# IWRL6432 register map
File version: 1.0
CPU: CM4 1.0, other endian, MPU, FPU, 3 interrupt priority bits
Registers are 32-bit, read-write, reset 0x0 unless marked. A register's access mark holds for its fields unless they carry their own. Offsets are from the block's base; [hi:lo] are bit positions; {n}, {i} and the like mark numbered series.

## APP_CRC
Base 0x54020000
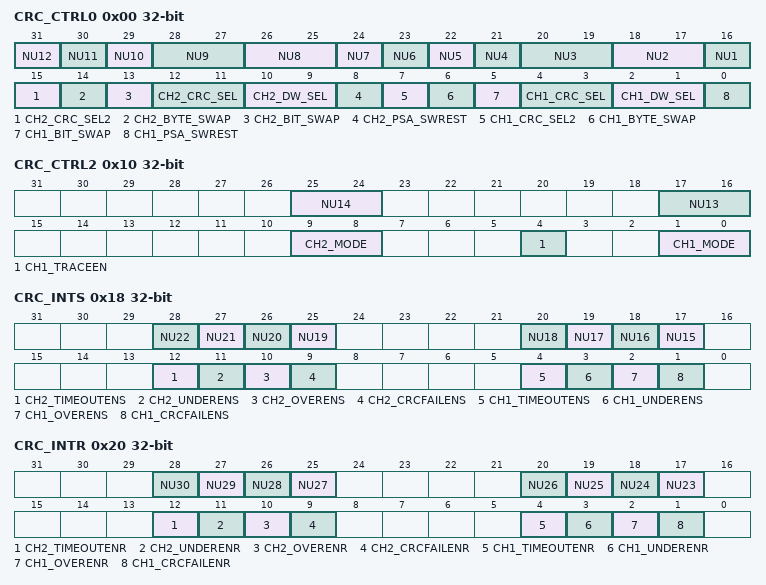
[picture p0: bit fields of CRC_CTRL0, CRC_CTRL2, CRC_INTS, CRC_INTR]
0x00 CRC_CTRL0 — Contains sw reset control bit to reset PSA
  [31] NU12 — [31:31] Reserved
  [30] NU11 — [30:30] Reserved
  [29] NU10 — [29:29] Reserved
  [28:27] NU9 — [28:27] Reserved
  [26:25] NU8 — [26:25] Reserved
  [n+17] NU{n} (n=4..7) — [{n+17}:{n+17}] Reserved
  [20:19] NU3 — [20:19] Reserved
  [18:17] NU2 — [18:17] Reserved
  [16] NU1 — [16:16] Reserved
  [15] CH2_CRC_SEL2 — [15:15] Refer "CH2_DW_SEL" field description
  [14] CH2_BYTE_SWAP — [14:14] BYTE SWAP Enable across Data Size 0 ΓÇô Byte Swap Disabled 1 ΓÇô Byte Swap enabled.
  [13] CH2_BIT_SWAP — [13:13] msb/lsb SWAPPING 0 ΓÇô msb (most significant bit First) 1 ΓÇô lsb (least significant bit First)
  [12:11] CH2_CRC_SEL — [12:11] CRC type select. {CH1_CRC_SEL2,CH1_CRC_SEL[1:0]} 000 ΓÇô CRC-64 001 - CRC-16 010 ΓÇô CRC-32 100 - VDA CAN, SAE-J1850 CRC-8 101 - H2F, Autosar 4.0 110 - CASTAGNOLI, iSCSI 111 / 011 - E2E Profile 4
  [10:9] CH2_DW_SEL — [10:9] CRC Data Size select. 000 ΓÇô Not Supported 001 - 16 bit Data Size 010 ΓÇô 32 Bit Data Size
  [8] CH2_PSA_SWREST — [8:8] Channel 2 PSA Software Reset. When set, the PSA Signature Register is reset to all zero. Software reset does not reset software reset bit itself. Therefore, CPU is required to clear this bit by writing a ΓÇÿ0ΓÇÖ. 0 = PSA Signature Register not reset 1 = PSA Signature Register reset
  [7] CH1_CRC_SEL2 — [7:7] Refer "CH1_DW_SEL" field description
  [6] CH1_BYTE_SWAP — [6:6] BYTE SWAP Enable across Data Size 0 ΓÇô Byte Swap Disabled 1 ΓÇô Byte Swap enabled.
  [5] CH1_BIT_SWAP — [5:5] msb/lsb SWAPPING 0 ΓÇô msb (most significant bit First) 1 ΓÇô lsb (least significant bit First)
  [4:3] CH1_CRC_SEL — [4:3] CRC type select. {CH1_CRC_SEL2,CH1_CRC_SEL[1:0]} 000 ΓÇô CRC-64 001 - CRC-16 010 ΓÇô CRC-32 100 - VDA CAN, SAE-J1850 CRC-8 101 - H2F, Autosar 4.0 110 - CASTAGNOLI, iSCSI 111 / 011 - E2E Profile 4
  [2:1] CH1_DW_SEL — [2:1] CRC Data Size select. 000 ΓÇô Not Supported 001 - 16 bit Data Size 010 ΓÇô 32 Bit Data Size
  [0] CH1_PSA_SWREST — [0:0] Channel 1 PSA Software Reset. When set, the PSA Signature Register is reset to all zero. Software reset does not reset software reset bit itself. Therefore, CPU is required to clear this bit by writing a ΓÇÿ0ΓÇÖ. 0 = PSA Signature Register not reset 1 = PSA Signature Register reset
0x08 CRC_CTRL1 — Contains power down control bit
  [0] PWDN — [0:0] Power Down. When set, MCRC moduleMCRC Module is put in power down mode. 0 = MCRC is not in power down mode 1 = MCRC is in power down mode
0x10 CRC_CTRL2 — Contains channel mode, data trace enable control bits
  [25:24] NU14 — [25:24] Reserved
  [17:16] NU13 — [17:16] Reserved
  [9:8] CH2_MODE — [9:8] Channel 2 Mode: 0 0 = Data Capture mode. In this mode, the PSA Signature Register does not compress data when it is written. Any data written to PSA Signature Register is simply captured by PSA Signature Register without any compression. This mode can be used to plant seed value into the PSA register 0 1 = AUTO mode 1 0 = reserved 1 1 = Full-CPU mode
  [4] CH1_TRACEEN — [4:4] Channel 1 Data Trace Enable. When set, the channel is put into data trace mode. The channel snoops on the CPU VBUSM, ITCM, DTCM buses for any read transaction. Any read data on these buses is compressed by the PSA Signature Register. When suspend is on, the PSA Signature Register does not compress any read data on these buses. 0 = Data Trace disable 1 = Data Trace enable
  [1:0] CH1_MODE — [1:0] Channel 1 Mode: 0 0 = Data Capture mode. In this mode, the PSA Signature Register does not compress data when it is written. Any data written to PSA Signature Register is simply captured by PSA Signature Register without any compression. This mode can be used to plant seed value into the PSA register 0 1 = AUTO mode 1 0 = reserved 1 1 = Full-CPU mode
0x18 CRC_INTS — Write one to a bit to enable a interrupt
  [n+6] NU{n} (n=19..22) — [{n+6}:{n+6}] Reserved
  [n+2] NU{n} (n=15..18) — [{n+2}:{n+2}] Reserved
  [12] CH2_TIMEOUTENS — [12:12] Channel 2 Timeout Interrupt Enable Bit. Writing a one to this bit enable the timeout interrupt. Writing a zero has no effect. Reading from this bit gives the status (interrupt enable/disable). User and privileged mode read: 0 = Timeout Interrupt disable 1 = Timeout Interrupt enable User and privileged mode write: 0 = Has no effect 1 = Timeout Interrupt enable
  [11] CH2_UNDERENS — [11:11] Channel 2 Underrun Interrupt Enable Bit. Writing a one to this bit enable the underrun interrupt. Writing a zero has no effect. Reading from this bit gives the status (interrupt enable/disable). User and privileged mode read: 0 = Underrun Interrupt disable 1 = Underrun Interrupt enable User and privileged mode write: 0 = Has no effect 1 = Underrun Interrupt enable
  [10] CH2_OVERENS — [10:10] Channel 2 Overrun Interrupt Enable Bit. Writing a one to this bit enable the overrun interrupt. Writing a zero has no effect. Reading from this bit gives the status (interrupt enable/disable). User and privileged mode read: 0 = Overrun Interrupt disable 1 = Overrun Interrupt enable User and privileged mode write: 0 = Has no effect 1 = Overrun Interrupt enable
  [9] CH2_CRCFAILENS — [9:9] Channel 2 CRC Fail Interrupt Enable Bit. Writing a one to this bit enable the CRC fail interrupt. Writing a zero has no effect. Reading from this bit gives the status (interrupt enable/disable). User and privileged mode read: 0 = CRC Fail Interrupt disable 1 = CRC Fail Interrupt enable User and privileged mode write: 0 = Has no effect 1 = CRC Fail Interrupt enable
  [4] CH1_TIMEOUTENS — [4:4] Channel 1 Timeout Interrupt Enable Bit. Writing a one to this bit enable the timeout interrupt. Writing a zero has no effect. Reading from this bit gives the status (interrupt enable/disable). User and privileged mode read: 0 = Timeout Interrupt disable 1 = Timeout Interrupt enable User and privileged mode write: 0 = Has no effect 1 = Timeout Interrupt enable
  [3] CH1_UNDERENS — [3:3] Channel 1 Underrun Interrupt Enable Bit. Writing a one to this bit enable the underrun interrupt. Writing a zero has no effect. Reading from this bit gives the status (interrupt enable/disable). User and privileged mode read: 0 = Underrun Interrupt disable 1 = Underrun Interrupt enable User and privileged mode write: 0 = Has no effect 1 = Underrun Interrupt enable
  [2] CH1_OVERENS — [2:2] Channel 1 Overrun Interrupt Enable Bit. Writing a one to this bit enable the overrun interrupt. Writing a zero has no effect. Reading from this bit gives the status (interrupt enable/disable). User and privileged mode read: 0 = Overrun Interrupt disable 1 = Overrun Interrupt enable User and privileged mode write: 0 = Has no effect 1 = Overrun Interrupt enable
  [1] CH1_CRCFAILENS — [1:1] Channel 1 CRC Fail Interrupt Enable Bit. Writing a one to this bit enable the CRC fail interrupt. Writing a zero has no effect. Reading from this bit gives the status (interrupt enable/disable). User and privileged mode read: 0 = CRC Fail Interrupt disable 1 = CRC Fail Interrupt enable User and privileged mode write: 0 = Has no effect 1 = CRC Fail Interrupt enable
0x20 CRC_INTR — Write one to a bit to disable a interrupt
  [n-2] NU{n} (n=27..30) — [{n-2}:{n-2}] Reserved
  [n-6] NU{n} (n=23..26) — [{n-6}:{n-6}] Reserved
  [12] CH2_TIMEOUTENR — [12:12] Channel 2 Timeout Interrupt Disable Bit. Writing a one to this bit disable the timeout interrupt. Writing a zero has no effect. Reading from this bit gives the status (interrupt enable/disable). User and privileged mode read: 0 = Timeout Interrupt disable 1 = Timeout Interrupt enable User and privileged mode write: 0 = Has no effect 1 = Timeout Interrupt disable
  [11] CH2_UNDERENR — [11:11] Channel 2 Underrun Interrupt Disable Bit. Writing a one to this bit disable the underrun interrupt. Writing a zero has no effect. Reading from this bit gives the status (interrupt enable/dis- able). User and privileged mode read: 0 = Underrun Interrupt disable 1 = Underrun Interrupt enable User and privileged mode write: 0 = Has no effect 1 = Underrun Interrupt disable
  [10] CH2_OVERENR — [10:10] Channel 2 Overrun Interrupt Disable Bit. Writing a one to this bit disable the overrun interrupt. Writing a zero has no effect. Reading from this bit gives the status (interrupt enable/disable). User and privileged mode read: 0 = Overrun Interrupt disable 1 = Overrun Interrupt enable User and privileged mode write: 0 = Has no effect 1 = Overrun Interrupt disable
  [9] CH2_CRCFAILENR — [9:9] Channel 2 CRC Fail Interrupt Disable Bit. Writing a one to this bit disable the CRC fail interrupt. Writing a zero has no effect. Reading from this bit gives the status (interrupt enable/disable). User and privileged mode read: 0 = CRC Fail Interrupt disable 1 = CRC Fail Interrupt enable User and privileged mode write: 0 = Has no effect 1 = CRC Fail Interrupt disable
  [4] CH1_TIMEOUTENR — [4:4] Channel 1 Timeout Interrupt Disable Bit. Writing a one to this bit disable the timeout interrupt. Writing a zero has no effect. Reading from this bit gives the status (interrupt enable/disable). User and privileged mode read: 0 = Timeout Interrupt disable 1 = Timeout Interrupt enable User and privileged mode write: 0 = Has no effect 1 = Timeout Interrupt disable
  [3] CH1_UNDERENR — [3:3] Channel 1 Underrun Interrupt Disable Bit. Writing a one to this bit disable the underrun interrupt. Writing a zero has no effect. Reading from this bit gives the status (interrupt enable/dis- able). User and privileged mode read: 0 = Underrun Interrupt disable 1 = Underrun Interrupt enable User and privileged mode write: 0 = Has no effect 1 = Underrun Interrupt disable
  [2] CH1_OVERENR — [2:2] Channel 1 Overrun Interrupt Disable Bit. Writing a one to this bit disable the overrun interrupt. Writing a zero has no effect. Reading from this bit gives the status (interrupt enable/disable). User and privileged mode read: 0 = Overrun Interrupt disable 1 = Overrun Interrupt enable User and privileged mode write: 0 = Has no effect 1 = Overrun Interrupt disable
  [1] CH1_CRCFAILENR — [1:1] Channel 1 CRC Fail Interrupt Disable Bit. Writing a one to this bit disable the CRC fail interrupt. Writing a zero has no effect. Reading from this bit gives the status (interrupt enable/disable). User and privileged mode read: 0 = CRC Fail Interrupt disable 1 = CRC Fail Interrupt enable User and privileged mode write: 0 = Has no effect 1 = CRC Fail Interrupt disable
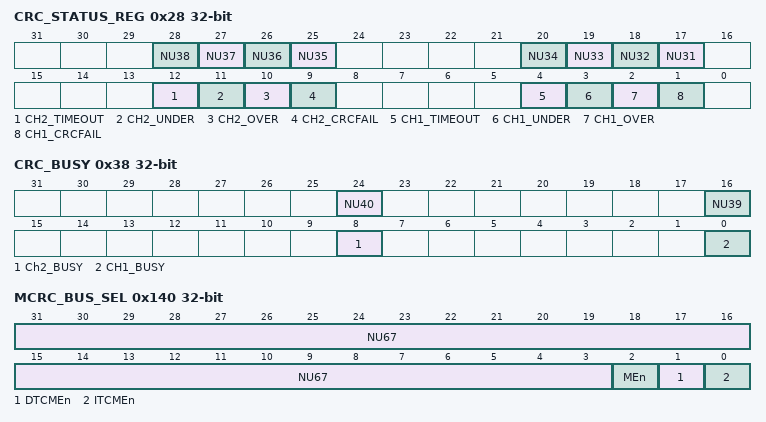
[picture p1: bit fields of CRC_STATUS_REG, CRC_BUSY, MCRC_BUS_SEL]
0x28 CRC_STATUS_REG — Contains interrupt flags for different types of interrupt
  [n-10] NU{n} (n=35..38) — [{n-10}:{n-10}] Reserved
  [n-14] NU{n} (n=31..34) — [{n-14}:{n-14}] Reserved
  [12] CH2_TIMEOUT — [12:12] Channel 2 CRC Timeout Status Flag. This bit is cleared by writing a ΓÇÖ1ΓÇÖ to it only. Writing ΓÇÖ0ΓÇÖ has no effect. This bit is set in AUTO mode. 0 = No timeout interrupt is active 1 = Timeout interrupt is active
  [11] CH2_UNDER — [11:11] Channel 2 CRC Underrun Status Flag. This bit is cleared by writing a ΓÇÖ1ΓÇÖ to it only. Writing ΓÇÖ0ΓÇÖ has no effect. This bit is set in AUTO mode only 0 = No underrun interrupt is active 1 = Underrun interrupt is active
  [10] CH2_OVER — [10:10] Channel 2 CRC Overrun Status Flag. This bit is cleared by writing a ΓÇÖ1ΓÇÖ to it only. Writing ΓÇÖ0ΓÇÖ has no effect. This bit is set in AUTO mode 0 = No overrun interrupt is active 1 = Overrun interrupt is active
  [9] CH2_CRCFAIL — [9:9] Channel 2 CRC Compare Fail Status Flag. This bit is cleared by writing a ΓÇÖ1ΓÇÖ to it only. Writing ΓÇÖ0ΓÇÖ has no effect. This bit is set in AUTO mode only. 0 = No CRC compare fail interrupt is active 1 = CRC compare fail interrupt is active
  [4] CH1_TIMEOUT — [4:4] Channel 1 CRC Timeout Status Flag. This bit is cleared by writing a ΓÇÖ1ΓÇÖ to it only. Writing ΓÇÖ0ΓÇÖ has no effect. This bit is set in AUTO mode. 0 = No timeout interrupt is active 1 = Timeout interrupt is active
  [3] CH1_UNDER — [3:3] Channel 1 CRC Underrun Status Flag. This bit is cleared by writing a ΓÇÖ1ΓÇÖ to it only. Writing ΓÇÖ0ΓÇÖ has no effect. This bit is set in AUTO mode only 0 = No underrun interrupt is active 1 = Underrun interrupt is active
  [2] CH1_OVER — [2:2] Channel 1 CRC Overrun Status Flag. This bit is cleared by writing a ΓÇÖ1ΓÇÖ to it only. Writing ΓÇÖ0ΓÇÖ has no effect. This bit is set in AUTO mode 0 = No overrun interrupt is active 1 = Overrun interrupt is active
  [1] CH1_CRCFAIL — [1:1] Channel 1 CRC Compare Fail Status Flag. This bit is cleared by writing a ΓÇÖ1ΓÇÖ to it only. Writing ΓÇÖ0ΓÇÖ has no effect. This bit is set in AUTO mode only. 0 = No CRC compare fail interrupt is active 1 = CRC compare fail interrupt is active
0x30 CRC_INT_OFFSET_REG — Contains the interrupt offset vector address
  [7:0] OFSTREG — [7:0] CRC Interrupt Offset. This register indicates the highest priority pending interrupt vector address. Reading the offset register auto- matically clear the respective interrupt flag. Please reference Table 1ΓÇô3. for details.
0x38 CRC_BUSY — Contains the busy flag for each channel
  [24] NU40 — [24:24] Reserved
  [16] NU39 — [16:16] Reserved
  [8] Ch2_BUSY — [8:8] Ch2_BUSY. During AUTO mode, the busy flag is set when the first data pattern of the block is compressed and remains set until the the last data pattern of the block is compressed. The flag is cleared when the last data pattern of the block is compressed.
  [0] CH1_BUSY — [0:0] CH1_BUSY. During AUTO mode, the busy flag is set when the first data pattern of the block is compressed and remains set until the the last data pattern of the block is compressed. The flag is cleared when the last data pattern of the block is compressed.
0x40 CRC_PCOUNT_REG1 — Channel 1 preload register for the pattern count
  [19:0] CRC_PAT_COUNT1 — [19:0] Channel 1 Pattern Counter Preload Register. This register con- tains the number of data patterns in one sector to be compressed before a CRC is performed.
0x44 CRC_SCOUNT_REG1 — Channel 1 preload register for the sector count
  [15:0] CRC_SEC_COUNT1 — [15:0] Channel 1 Sector Counter Preload Register. This register con- tains the number of sectors in one block of memory.
0x48 CRC_CURSEC_REG1 — Channel 1 current sector register contains the sector number which causes CRC failure
  [15:0] CRC_CURSEC1 — [15:0] Channel 1 Current Sector ID Register. In AUTO mode, this register contains the current sector number of which the signature verification fails. The sector counter is a free running up counter. When a sector fails, the erroneous sector number is logged into current sector ID register and the CRC fail interrupt is generated The sector ID register is frozen until it is read and the CRC fail status bit is cleared by CPU. While it is frozen, it does not capture another erroneous sector number. When this condition happens, an overrun interrupt is generated instead. Once the register is read and the CRC fail interrupt flag is cleared it can capture new erro- neous sector number.
0x4C CRC_WDTOPLD1 — Channel 1 timeout pre-load value to check if within a given time DMA initiates a block transfer
  [23:0] CRC_WDTOPLD1 — [23:0] Channel 1 Watchdog Timeout Counter Preload Register. This register contains the number of clock cycles within which the DMA must transfer the next block of data patterns.
0x50 CRC_BCTOPLD1 — Channel 1 timeout pre-load value to check if one block of patterns are compressed with a given time
  [23:0] CRC_BCTOPLD1 — [23:0] Channel 1 Block Complete Timeout Counter Preload Regis- ter. This register contains the number of clock cycles within which the CRC for an entire block needs to complete before a timeout interrupt is generated.
0x60 PSA_SIGREGL1 — Channel 1 PSA signature low register
  [31:0] PSASIG1_31_0 — [31:0] Channel 1 PSA Signature Low Register. This register contains the value stored at PSASIG1[31:0] register.
0x64 PSA_SIGREGH1 — Channel 1 PSA signature high register
  [31:0] PSA_SIG1_63_32 — [31:0] Channel 1 PSA Signature High Register. This register contains the value stored at PSASIG1[63:32] register.
0x68 CRC_REGL1 — Channel 1 CRC value low register
  [31:0] CRC1_31_0 — [31:0] Channel 1 CRC Value Low Register. This register contains the current known good signature value stored at CRC1[31:0] regis- ter.
0x6C CRC_REGH1 — Channel 1 CRC value high register
  [31:0] CRC1_63_32 — [31:0] Channel 1 CRC Value High Register. This register contains the current known good signature value stored at CRC1[63:32] regis- ter.
0x70 PSA_SECSIGREGL1 — Channel 1 PSA sector signature low regis-ter
  [31:0] PSASECSIG1_31_0 — [31:0] Channel 1 PSA Sector Signature Low Register. This register contains the value stored at PSASECSIG1[31:0] register.
0x74 PSA_SECSIGREGH1 — Channel 1 PSA sector signature high regis-ter
  [31:0] PSASECSIG1_63_32 — [31:0] Channel 1 PSA Sector Signature High Register. This register contains the value stored at PSASECSIG1[63:32] register.
0x78 RAW_DATAREGL1 — Channel 1 un-compressed raw data low register
  [31:0] RAW_DATA1_31_0 — [31:0] Channel 1 Raw Data Low Register. This register contains bit 31:0 of the un-compressed raw data.
0x7C RAW_DATAREGH1 — Channel 1 un-compressed raw data high register
  [31:0] RAW_DATA1_63_32 — [31:0] Channel 1 Raw Data High Register. This register contains bit 63:32 of the un-compressed raw data.
0x80 CRC_PCOUNT_REG2 — Channel 2 preload register for the pattern count
  [19:0] CRC_PAT_COUNT2 — [19:0] Channel 2 Pattern Counter Preload Register. This register con- tains the number of data patterns in one sector to be compressed before a CRC is performed.
0x84 CRC_SCOUNT_REG2 — Channel 2 preload register for the sector count
  [15:0] CRC_SEC_COUNT2 — [15:0] Channel 2 Sector Counter Preload Register. This register con- tains the number of sectors in one block of memory.
0x88 CRC_CURSEC_REG2 — Channel 2 current sector register contains the sector number which causes CRC fail-ure
  [15:0] CRC_CURSEC2 — [15:0] Channel 2 Current Sector ID Register. In AUTO mode, this register contains the current sector number of which the signature verification fails. The sector counter is a free running up counter. When a sector fails, the erroneous sector number is logged into current sector ID register and the CRC fail interrupt is generated The sector ID register is frozen until it is read and the CRC fail status bit is cleared by CPU. While it is frozen, it does not capture another erroneous sector number. When this condition happens, an overrun interrupt is generated instead. Once the register is read and the CRC fail interrupt flag is cleared it can capture new erro- neous sector number.
0x8C CRC_WDTOPLD2 — Channel 2 timeout pre-load value to check if within a given time DMA initiates a block transfer
  [23:0] CRC_WDTOPLD2 — [23:0] Channel 2 Watchdog Timeout Counter Preload Register. This register contains the number of clock cycles within which the DMA must transfer the next block of data patterns.
0x90 CRC_BCTOPLD2 — Channel 2 timeout pre-load value to check if one block of patterns are compressed with a given time
  [23:0] CRC_BCTOPLD2 — [23:0] Channel 2 Block Complete Timeout Counter Preload Regis- ter. This register contains the number of clock cycles within which the CRC for an entire block needs to complete before a timeout interrupt is generated.
0xA0 PSA_SIGREGL2 — Channel 2 PSA signature low register
  [31:0] PSASIG2_31_0 — [31:0] Channel 2 PSA Signature Low Register. This register contains the value stored at PSASIG2[31:0] register.
0xA4 PSA_SIGREGH2 — Channel 2 PSA signature high register
  [31:0] PSA_SIG2_63_32 — [31:0] Channel 2 PSA Signature High Register. This register contains the value stored at PSASIG2[63:32] register.
0xA8 CRC_REGL2 — Channel 2 CRC value low register
  [31:0] CRC2_31_0 — [31:0] Channel 2 CRC Value Low Register. This register contains the current known good signature value stored at CRC2[31:0] regis- ter.
0xAC CRC_REGH2 — Channel 2 CRC value high register
  [31:0] CRC2_63_32 — [31:0] Channel 2 CRC Value High Register. This register contains the current known good signature value stored at CRC2[63:32] regis- ter.
0xB0 PSA_SECSIGREGL2 — Channel 2 PSA sector signature low regis-ter
  [31:0] PSASECSIG2_31_0 — [31:0] Channel 2 PSA Sector Signature Low Register. This register contains the value stored at PSASECSIG2[31:0] register.
0xB4 PSA_SECSIGREGH2 — Channel 2 PSA sector signature high regis-ter
  [31:0] PSASECSIG2_63_32 — [31:0] Channel 2 PSA Sector Signature High Register. This register contains the value stored at PSASECSIG2[63:32] register.
0xB8 RAW_DATAREGL2 — Channel 2 un-compressed raw data low register
  [31:0] RAW_DATA2_31_0 — [31:0] Channel 2 Raw Data Low Register. This register contains bit 31:0 of the un-compressed raw data.
0xBC RAW_DATAREGH2 — Channel 2 un-compressed raw data high Register
  [31:0] RAW_DATA2_63_32 — [31:0] Channel 2 Raw Data High Register. This register contains bit 63:32 of the un-compressed raw data.
0xC0 CRC_PCOUNT_REG3 — Channel 3 preload register for the pattern count
  [19:0] NU41 — [19:0] Reserved
0xC4 CRC_SCOUNT_REG3 — Channel 3 preload register for the sector count
  [15:0] NU42 — [15:0] Reserved
0xC8 CRC_CURSEC_REG3 — Channel 3 current sector register contains the sector number which causes CRC fail-ure
  [15:0] NU43 — [15:0] Reserved
0xCC CRC_WDTOPLD3 — Channel 3 timeout pre-load value to check if within a given time DMA initiates a block transfer
  [23:0] NU44 — [23:0] Reserved
0xD0 CRC_BCTOPLD3 — Channel 3 timeout pre-load value to check if one block of patterns are compressed with a given time
  [23:0] NU45 — [23:0] Reserved
0xE0 PSA_SIGREGL3 — Channel 3 PSA signature low register
  [31:0] NU46 — [31:0] Reserved
0xE4 PSA_SIGREGH3 — Channel 3 PSA signature high register
  [31:0] NU47 — [31:0] Reserved
0xE8 CRC_REGL3 — Channel 3 CRC value low register
  [31:0] NU48 — [31:0] Reserved
0xEC CRC_REGH3 — Channel 3 CRC value high register
  [31:0] NU49 — [31:0] Reserved
0xF0 PSA_SECSIGREGL3 — Channel 3 PSA sector signature low regis-ter
  [31:0] NU50 — [31:0] Reserved
0xF4 PSA_SECSIGREGH3 — Channel 3 PSA sector signature high regis-ter
  [31:0] NU51 — [31:0] Reserved
0xF8 RAW_DATAREGL3 — Channel 3 un-compressed raw data low register
  [31:0] NU52 — [31:0] Reserved
0xFC RAW_DATAREGH3 — Channel 3 un-compressed raw data high Register
  [31:0] NU53 — [31:0] Reserved
0x100 CRC_PCOUNT_REG4 — Channel 4 preload register for the pattern count
  [19:0] NU54 — [19:0] Reserved
0x104 CRC_SCOUNT_REG4 — Channel 4 preload register for the sector count
  [15:0] NU55 — [15:0] Reserved
0x108 CRC_CURSEC_REG4 — Channel 4 current sector register contains the sector number which causes CRC fail-ure
  [15:0] NU56 — [15:0] Reserved
0x10C CRC_WDTOPLD4 — Channel 4 timeout pre-load value to check if within a given time DMA initiates a block transfer
  [23:0] NU57 — [23:0] Reserved
0x110 CRC_BCTOPLD4 — Channel 4 timeout pre-load value to check if one block of patterns are compressed with a given time
  [23:0] NU58 — [23:0] Reserved
0x120 PSA_SIGREGL4 — Channel 4 PSA signature low register
  [31:0] NU59 — [31:0] Reserved
0x124 PSA_SIGREGH4 — Channel 4 PSA signature high register
  [31:0] NU60 — [31:0] Reserved
0x128 CRC_REGL4 — Channel 4 CRC value low register
  [31:0] NU61 — [31:0] Reserved
0x12C CRC_REGH4 — Channel 4 CRC value high register
  [31:0] NU62 — [31:0] Reserved
0x130 PSA_SECSIGREGL4 — Channel 4 PSA sector signature low regis-ter
  [31:0] NU63 — [31:0] Reserved
0x134 PSA_SECSIGREGH4 — Channel 4 PSA sector signature high regis-ter
  [31:0] NU64 — [31:0] Reserved
0x138 RAW_DATAREGL4 — Channel 4 un-compressed raw data low register
  [31:0] NU65 — [31:0] Reserved
0x13C RAW_DATAREGH4 — Channel 4 un-compressed raw data high Register
  [31:0] NU66 — [31:0] Reserved
0x140 MCRC_BUS_SEL — Disables either or all tracing of data buses
  [31:3] NU67 — [31:3] Reserved
  [2] MEn — [2:2] MEn. Enable/disables the tracing of VBUSM 0: Tracing of VBUSM master bus has been disabled 1: Tracing of VBUSM master bus has been enabled
  [1] DTCMEn — [1:1] DTCMEn. Enable/disables the tracing of data TCM 0: Tracing of DTCM_ODD and DTCM_EVEN buses have been disabled 1: Tracing of DTCM_ODD and DTCM_EVEN buses have been enabled
  [0] ITCMEn — [0:0] ITCMEn. Enable/disables the tracing of instruction TCM 0: Tracing of ITCM bus has been disabled 1: Tracing of ITCM bus has been enabled
0x144 MCRC_RESERVED — 0x144 to 0x1FF is reserved area.
  [31:0] NU68 — [31:0] 0x144 to 0x1FF is reserved area.
